# nrf7140_application register map
Vendor: Nordic Semiconductor; Series: nRF71; File version: 1
CPU: CM33 r0p4, little endian, MPU, FPU, 3 interrupt priority bits, 480 interrupts, 8 SAU regions
Registers are 32-bit, read-write, reset 0x0 unless marked. A register's access mark holds for its fields unless they carry their own. Offsets are from the block's base; [hi:lo] are bit positions; lines under a group give offsets from that group; {n}, {i} and the like mark numbered series; 'fields as' and 'values as' point back to an identical list.

## GLOBAL_GPU_NS — GPU
Base 0x49000000
0x100 EVENTS_CORE — Event indicating that interrupt triggered at GPU core
  [0] EVENTS_CORE
    0=NotGenerated (Event not generated); 1=Generated (Event generated)
0x104 EVENTS_SYSERROR — Event indicating
  [0] EVENTS_SYSERROR
    values as EVENTS_CORE.EVENTS_CORE
0x108 EVENTS_FREEZE — Freeze GPU
  [0] EVENTS_FREEZE
    values as EVENTS_CORE.EVENTS_CORE
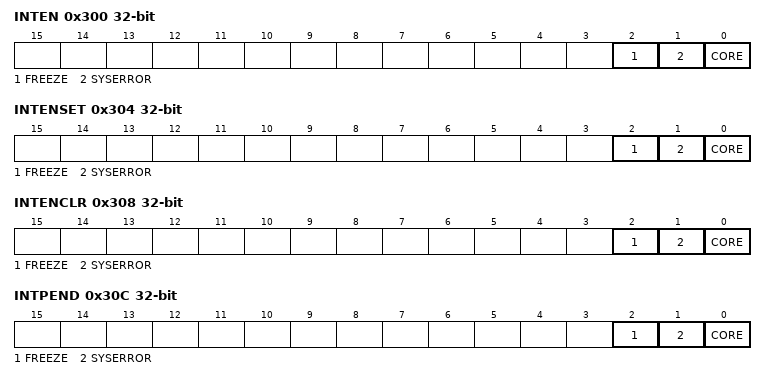
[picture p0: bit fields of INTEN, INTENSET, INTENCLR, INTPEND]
0x300 INTEN — Enable or disable interrupt
  [all] fields
    0=Disabled; 1=Enabled
  [2] FREEZE — Enable or disable interrupt for event FREEZE
  [1] SYSERROR — Enable or disable interrupt for event SYSERROR
  [0] CORE — Enable or disable interrupt for event CORE
0x304 INTENSET — Enable interrupt
  [all] fields
    on read: 0=Disabled (Read: Disabled); 1=Enabled (Read: Enabled) | on write: 1=Set (Enable)
  [2] FREEZE — Write '1' to enable interrupt for event FREEZE
  [1] SYSERROR — Write '1' to enable interrupt for event SYSERROR
  [0] CORE — Write '1' to enable interrupt for event CORE
0x308 INTENCLR — Disable interrupt
  [all] fields
    on read: 0=Disabled (Read: Disabled); 1=Enabled (Read: Enabled) | on write: 1=Clear (Disable)
  [2] FREEZE — Write '1' to disable interrupt for event FREEZE
  [1] SYSERROR — Write '1' to disable interrupt for event SYSERROR
  [0] CORE — Write '1' to disable interrupt for event CORE
0x30C INTPEND ro — Pending interrupts
  [all] fields
    on read: 0=NotPending (Read: Not pending); 1=Pending (Read: Pending)
  [2] FREEZE — Read pending status of interrupt for event FREEZE
  [1] SYSERROR — Read pending status of interrupt for event SYSERROR
  [0] CORE — Read pending status of interrupt for event CORE
0x500 ENABLE — Enable GPU.
  [0] EN — Enable
    0=Disabled (GPU disabled.); 1=Enabled (GPU enabled.)
0x504 FLAG — FLAG information for FREEZE assertion.
  [3:0] FLAG — Writing '1' sets the flag breakpoint, writing '0' resumes the breakpoint. Reading reads the value of the flag.
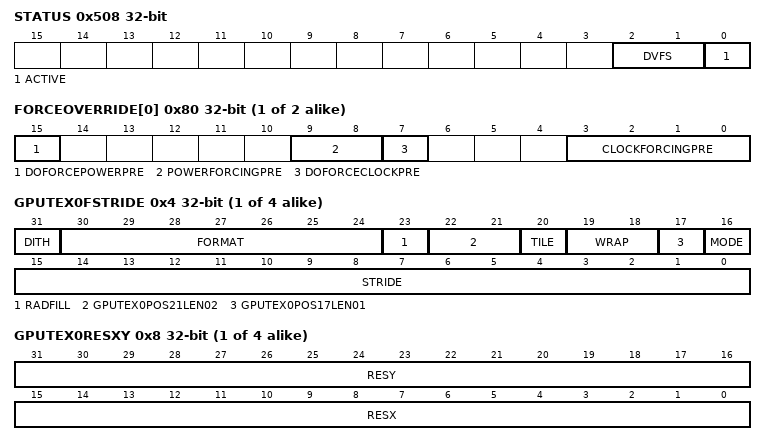
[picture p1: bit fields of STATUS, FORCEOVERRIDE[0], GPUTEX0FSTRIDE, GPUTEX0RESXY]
0x508 STATUS — GPU ACTIVE and DVFS status fields.
  [2:1] DVFS — Frequency reduction request for GPU core clock.
  [0] ACTIVE — GPU active indication
    1=BUSY (GPU is Busy); 0=IDLE (GPU is idle)
0xF00 PCGCSLAVE group — Unspecified
  {0x0+4j} PENALTY[{j}] (j=0..1) reset 0xFFFFFFFC — Description collection: Penalty level for power/clock pair n. When FULL_PCP_ZERO feature is not supported, PENALTY[0] address overlaps the PENALTY0 address and register description for PENALTY[0] is not valid.
    [1:0] PENALTY — Penalty level
  0x00 PENALTY0 (alternate view of PENALTY[*]) — Penalty level for power/clock pair 0. The register description is valid only when FULL_PCP_ZERO feature is not supported
    [1:0] PENALTY ro — Penalty level
  {0x80+4j} FORCEOVERRIDE[{j}] (j=0..1) — Description collection: Force override of power/clock pair n.
    [15] DOFORCEPOWERPRE, [9:8] POWERFORCINGPRE, [7] DOFORCECLOCKPRE, [3:0] CLOCKFORCINGPRE
0x1000 CORE group — Unspecified
  {0x0+0x10*j} GPUTEX{j}BASE (j=0..3) — Base address of drawing surface {j}.
    [31:0] BASE — Specifies the base address or drawing surface {j}.
  {0x4+0x10*j} GPUTEX{j}FSTRIDE (j=0..3) — Image {j} Mode and Stride
    [31] DITH — If set for destination texture, enables color dithering.
    [30:24] FORMAT — Specifies the image format
    [23] RADFILL — Radial fill enable
    [22:21] GPUTEX{j}POS21LEN02 wo
    [20] TILE — Enables the Tile Mode.
    [19:18] WRAP — Specifies the image wrapping mode (applicable only for Textures not for Framebuffer).
    [17] GPUTEX{j}POS17LEN01 wo
    [16] MODE — Specifies the image mode (applicable only for Textures not for Framebuffer)
    [15:0] STRIDE — Specifies the image stride distance in bytes from one scanline to another (signed)
  {0x8+0x10*j} GPUTEX{j}RESXY (j=0..3) — Image {j} Resolution
    [31:16] RESY — Specifies the size of resolution Y
    [15:0] RESX — Specifies the size of resolution X
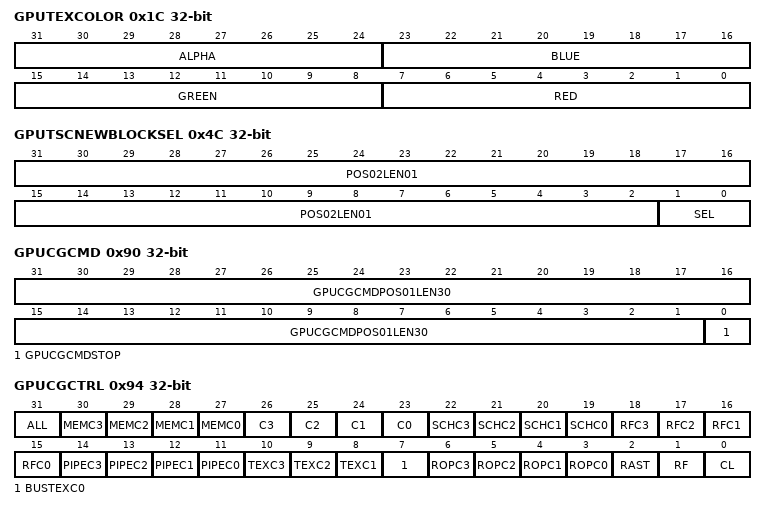
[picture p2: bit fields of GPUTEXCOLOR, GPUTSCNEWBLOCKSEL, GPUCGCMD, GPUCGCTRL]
  0x1C GPUTEXCOLOR — Texture Map's default color (for use with Luminance and Alpha-only color formats)
    [31:24] ALPHA — Specifies the Alpha (A) value
    [23:16] BLUE — Specifies the Blue (B) value
    [15:8] GREEN — Specifies the Green (G) value
    [7:0] RED — Specifies the Red (R) value
  0x48 GPUTSCNEWBLOCKTRIG — Trigger to reset TSc block.
    [31:0] POS00LEN32
  0x4C GPUTSCNEWBLOCKSEL — Select how TSc block will be reset.
    [31:2] POS02LEN01
    [1:0] SEL — 0: Reset TSc block when NEMA_DRAW_CMD_NOHOLD is written or tesselator starts new geometry or NEMA_TSC_NEW_BLOCK_TRIG is written.
  0x80 GPUBREAKPOINT — Debug feature. Specifies a Breakpoint on the Command List
    [31:0] GPUBREAKPOINT — Specifies the Breakpoint ID
  0x8C GPUBREAKPOINTMASK — Debug feature. Specifies a Breakpoint Mask.
    [31:0] MASK — Specifies the Breakpoint Mask
  0x90 GPUCGCMD — Enable Clock gating
    [31:1] GPUCGCMDPOS01LEN30 wo
    [0] GPUCGCMDSTOP wo — When set to 1, the clock stops
  0x94 GPUCGCTRL — Clock gating controller
    [31] ALL — Disable clock gating for all modules
    [30] MEMC3
    [29] MEMC2
    [28] MEMC1
    [27] MEMC0 — Disable clock gating for Core 0 Instruction Memory
    [26] C3
    [25] C2
    [24] C1
    [23] C0 — Disable clock gating for Core 0
    [22] SCHC3
    [21] SCHC2
    [20] SCHC1
    [19] SCHC0 — Disable clock gating for Core 0 Scheduler
    [18] RFC3
    [17] RFC2
    [16] RFC1
    [15] RFC0 — Disable clock gating for Core 0 Register File
    [14] PIPEC3
    [13] PIPEC2
    [12] PIPEC1
    [11] PIPEC0 — Disable clock gating for Core 0 Pipeline
    [10] TEXC3
    [9] TEXC2
    [8] TEXC1
    [7] BUSTEXC0 — Disable clock gating for the BusInterface (memory System) and Core 0 Texture Map
    [6] ROPC3
    [5] ROPC2
    [4] ROPC1
    [3] ROPC0 — Disable clock gating for the Render Output Unit of core 0
    [2] RAST — Disable clock gating for the NemaP Rasterizer
    [1] RF — Disable clock gating for the NemaP Configuration Register File
    [0] CL — Disable clock gating for the Command List Processor
  0x98 GPUDIRTYMIN reset 0xFFFFFFFF — Read the Dirty_Min value. Resets dirty region to resolution size on write function.
    [31:0] DIRTYMIN — Write any value to reset dirty region to resolution size
  0x9C GPUDIRTYMAX — Read the Dirty_Max value
    [31:0] DIRTYMAX ro — Read the Dirty_max value
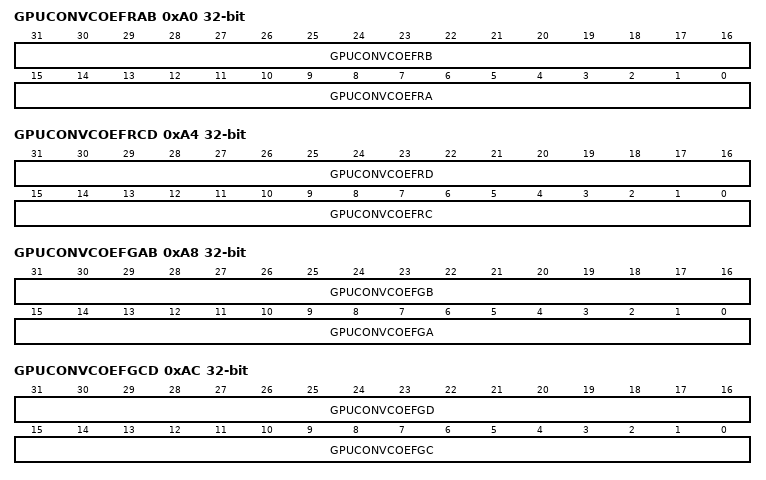
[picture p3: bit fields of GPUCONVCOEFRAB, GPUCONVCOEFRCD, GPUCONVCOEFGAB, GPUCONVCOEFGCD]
  0xA0 GPUCONVCOEFRAB — Specifies the YUV coefficients for Red color. Part one
    [31:16] GPUCONVCOEFRB — Specifies the YUV coefficients for Red color. Part B
    [15:0] GPUCONVCOEFRA — Specifies the YUV coefficients for Red color. Part A
  0xA4 GPUCONVCOEFRCD — Specifies the YUV coefficients for Red color. Part two
    [31:16] GPUCONVCOEFRD — Specifies the YUV coefficients for Red color. Part D
    [15:0] GPUCONVCOEFRC — Specifies the YUV coefficients for Red color. Part C
  0xA8 GPUCONVCOEFGAB — Specifies the YUV coefficients for Green color. Part one
    [31:16] GPUCONVCOEFGB — Specifies the YUV coefficients for Green color. Part B
    [15:0] GPUCONVCOEFGA — Specifies the YUV coefficients for Green color. Part A
  0xAC GPUCONVCOEFGCD — Specifies the YUV coefficients for Gren color. Part two
    [31:16] GPUCONVCOEFGD — Specifies the YUV coefficients for Green color. Part D
    [15:0] GPUCONVCOEFGC — Specifies the YUV coefficients for Green color. Part C
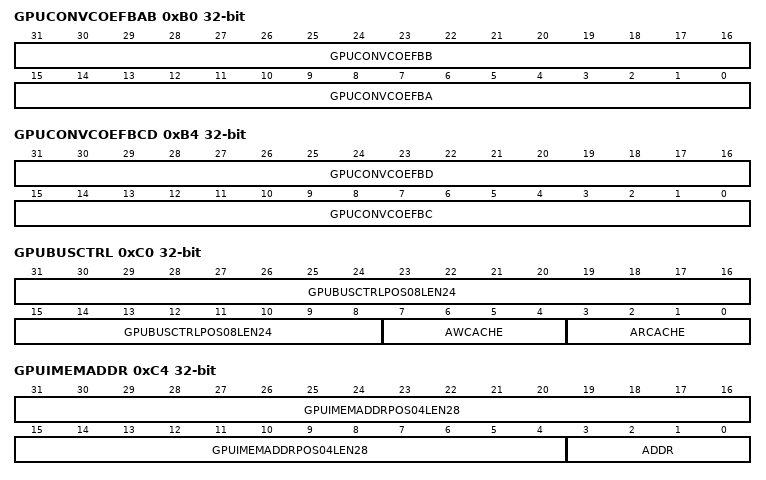
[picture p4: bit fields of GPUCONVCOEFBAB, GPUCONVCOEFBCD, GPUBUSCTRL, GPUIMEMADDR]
  0xB0 GPUCONVCOEFBAB — Specifies the YUV coefficients for Blue color. Part one
    [31:16] GPUCONVCOEFBB — Specifies the YUV coefficients for Blue color. Part B
    [15:0] GPUCONVCOEFBA — Specifies the YUV coefficients for Blue color. Part A
  0xB4 GPUCONVCOEFBCD — Specifies the YUV coefficients for Blue color. Part two
    [31:16] GPUCONVCOEFBD — Specifies the YUV coefficients for Blue color. Part D
    [15:0] GPUCONVCOEFBC — Specifies the YUV coefficients for Blue color. Part C
  0xB8 GPUCRCM0 — On read returns the CRC form Write Channel 0
    [31:0] GPUCRCM0 — NEMA_CRC_M0
  0xBC GPUCRCM1 — On read returns the CRC form Write Channel 1
    [31:0] GPUCRCM1 — NEMA_CRC_M1
  0xC0 GPUBUSCTRL — Indicates the value of the AWCACHE and the ARCACHE signals of the AXI Bus Interface.
    [31:8] GPUBUSCTRLPOS08LEN24
    [7:4] AWCACHE — Specifies the value of the output AWCACHE signal of the AXI Master Write Bus Interface
    [3:0] ARCACHE — Specifies the value of the output ARCACHE signal of the AXI Master Read Bus Interface
  0xC4 GPUIMEMADDR — Load shader instruction memory address. This register can be auto incremented. Its content
    [31:4] GPUIMEMADDRPOS04LEN28
    [3:0] ADDR — Specifies the load shader instruction memory address
  0xC8 GPUIMEMDATALOW — The lower bits (31-0) of the 64-bit load shader instruction memory data
    [31:0] IMEMDATALOW — Specifies the lower bits (31-0) of the load shader instruction memory data
  0xCC GPUIMEMDATAHIGH — The higher bits (63-32) of the 64-bit load shader instruction memory data
    [31:0] IMEMDATAHIGH — Specifies the higher bits (63-32) of the load shader instruction memory data
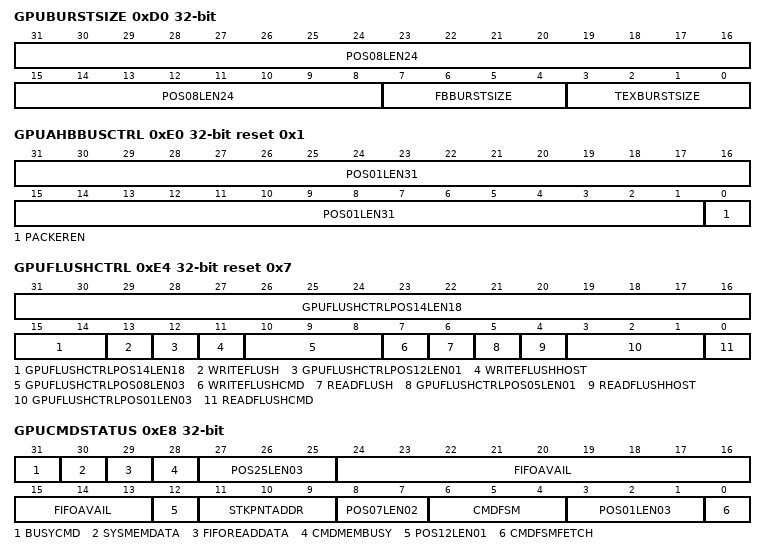
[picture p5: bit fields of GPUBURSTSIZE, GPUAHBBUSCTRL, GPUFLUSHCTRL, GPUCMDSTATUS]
  0xD0 GPUBURSTSIZE — Controls the size of the burst for the texture and framebuffer read.
    [31:8] POS08LEN24 ro
    [7:4] FBBURSTSIZE — Value of the framebuffer read burst size in log2(bytes).
    [3:0] TEXBURSTSIZE — Value of the texture read burst size in log2(bytes).
  0xE0 GPUAHBBUSCTRL reset 0x1 — Controls aspects of the AHB bus interface
    [31:1] POS01LEN31
    [0] PACKEREN — Enables or disables the packing of AHB transactions into 32-bit bursts when applicable
  0xE4 GPUFLUSHCTRL reset 0x7 — Controls the system flush
    [31:14] GPUFLUSHCTRLPOS14LEN18
    [13] WRITEFLUSH — When set to 1, flush write caches
    [12] GPUFLUSHCTRLPOS12LEN01
    [11] WRITEFLUSHHOST — If set to 1, the write caches are flushed when the Host triggers the Rasterizer (Register NEMA_DRAW_CMD_NOHOLD)
    [10:8] GPUFLUSHCTRLPOS08LEN03
    [7] WRITEFLUSHCMD — If set to 1, the write caches are flushed when the Command List Processor triggers the Rasterizer (Register NEMA_DRAW_CMD_NOHOLD)
    [6] READFLUSH — When set to 1, flush read caches
    [5] GPUFLUSHCTRLPOS05LEN01
    [4] READFLUSHHOST — If set to 1, the read caches are fluhsed when the Host triggers the Rasterizer (Register NEMA_DRAW_CMD_NOHOLD)
    [3:1] GPUFLUSHCTRLPOS01LEN03
    [0] READFLUSHCMD — If set to 1, the read caches are flushed when the Command List Processor triggers the Rasterizer (Register NEMA_DRAW_CMD_NOHOLD)
  0xE8 GPUCMDSTATUS — On read, returns internal CL processor status.
    [31] BUSYCMD — Indicates if the Command List Processor is busy
    [30] SYSMEMDATA — Indicates if there are data available in System Memory
    [29] FIFOREADDATA — Indicates if there are available data to read from FIFO
    [28] CMDMEMBUSY — Indicates if the Command List Processor System Memory is busy
    [27:25] POS25LEN03
    [24:13] FIFOAVAIL — Show how many cells are still available in FIFO
    [12] POS12LEN01
    [11:9] STKPNTADDR — Show the address of the stack pointer
    [8:7] POS07LEN02
    [6:4] CMDFSM — Indicates the state of CMDList internal FSM.
    [3:1] POS01LEN03
    [0] CMDFSMFETCH — Indicates the state of the FSM responsible for fetching
  0xEC GPUCMDRINGSTOP — Ring Buffer's pointer.
    [31:0] CMDRINGSTOP — Stores the Ring Buffer's last written address
  0xF0 GPUCMDADDR — Command list base address.
    [31:0] CMDADDR — Specifies the base address of every new command list ready to be executed
  0xF4 GPUCMDSIZE — Command list length in words(32-bits)
    [31:0] CMDSIZE — Specifies the length of the command list ready to be executed.
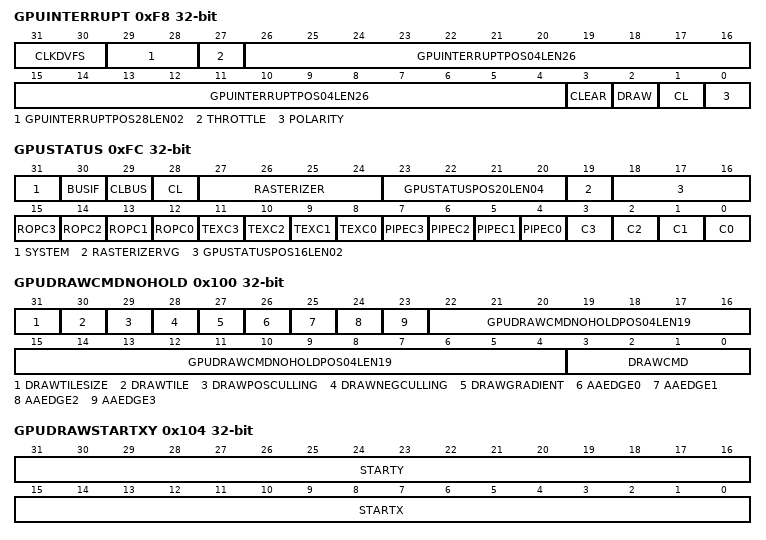
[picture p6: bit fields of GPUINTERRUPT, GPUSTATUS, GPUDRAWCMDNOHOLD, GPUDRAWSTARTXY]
  0xF8 GPUINTERRUPT — Interrupt control register
    [31:30] CLKDVFS — Specify the core_clk_dvfs output
    [29:28] GPUINTERRUPTPOS28LEN02
    [27] THROTTLE — When set to 1, the throttle signal will be ignored.
    [26:4] GPUINTERRUPTPOS04LEN26
    [3] CLEAR — When set to 1, the interrupt in the NEMA_IRQ_ID register is cleared
    [2] DRAW — When set to 1, signals an interrupt at the end of a drawing command
    [1] CL — When set to 1, signals an interrupt at the end of a command list
    [0] POLARITY — 1: IRQ signal is active low
  0xFC GPUSTATUS — On read, returns Nema's status.
    [31] SYSTEM — Indicates if the system is busy
    [30] BUSIF — Indicates if the Bus Interface Unit is busy
    [29] CLBUS — Indicates if the Command List bus is busy
    [28] CL — Indicates if the Command List Processor is busy
    [27:24] RASTERIZER — Indicate if the Rasterizer Unit is busy
    [23:20] GPUSTATUSPOS20LEN04
    [19] RASTERIZERVG — Indicates if the Rasterizer Vertex Matrix Multiplication Unit and Tesselation Unit are busy
    [18:16] GPUSTATUSPOS16LEN02
    [15] ROPC3
    [14] ROPC2
    [13] ROPC1
    [12] ROPC0 — Indicates if the Core 0 Render Output Unit is busy
    [11] TEXC3
    [10] TEXC2
    [9] TEXC1
    [8] TEXC0 — Indicates if the Core 0 Texture Map Unit is busy
    [7] PIPEC3
    [6] PIPEC2
    [5] PIPEC1
    [4] PIPEC0 — Indicates if the Core 0 graphics pipeline is busy
    [3] C3
    [2] C2
    [1] C1
    [0] C0 — Indicates if the Core 0 is busy
  0x100 GPUDRAWCMDNOHOLD — Rasterizer Command (e.g. draw triangle, rectangle etc)
    [31] DRAWTILESIZE — When set to 1, tile size is 2x2
    [30] DRAWTILE — When set to 1, tile mode is enabled
    [29] DRAWPOSCULLING — When set to 1, positive culling (counter-clockwise) is enabled
    [28] DRAWNEGCULLING — When set to 1, negative culling (clockwise) is enabled
    [27] DRAWGRADIENT — When set to 1, color gradient is enabled
    [26-n] AAEDGE{n} (n=0..3) — When set to 1, Antialiasing feature is enabled for edge {n}
    [22:4] GPUDRAWCMDNOHOLDPOS04LEN19
    [3:0] DRAWCMD — Draw Command
  0x104 GPUDRAWSTARTXY — Vertex 0 drawing primitive. This register is used only for integer values. For greater accuracy
    [31:16] STARTY — Specifies the Y coordinate (integer value) of vertex 0
    [15:0] STARTX — Specifies the X coordinate (integer value) of vertex 0
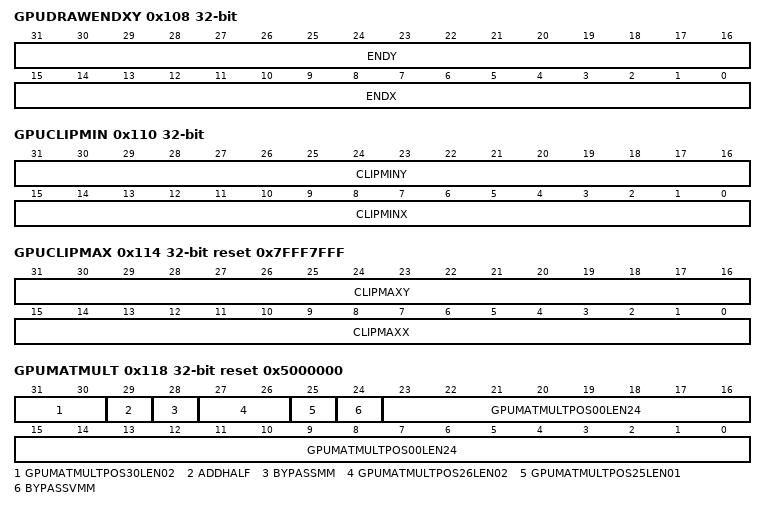
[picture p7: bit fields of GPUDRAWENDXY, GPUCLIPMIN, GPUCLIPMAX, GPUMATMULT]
  0x108 GPUDRAWENDXY — Vertex 1 drawing primitive. This register is used only for integer values. For greater accuracy
    [31:16] ENDY — Specifies the Y coordinate (integer value) of vertex 1
    [15:0] ENDX — Specifies the X coordinate (integer value) of vertex 1
  0x10C DRAWFANX — X coordinate of the Fan center point. Its content should be considered volatile.
    [31:0] X — Specifies the X coordinate of bezier vertex 4 drawing primitive (fixed point 16.16 format)
  0x110 GPUCLIPMIN — Clipping Rectangle upper left vertex
    [31:16] CLIPMINY — Define the upper left Y coordinate
    [15:0] CLIPMINX — Define the upper left X coordinate
  0x114 GPUCLIPMAX reset 0x7FFF7FFF — Clipping Rectangle bottom right vertex
    [31:16] CLIPMAXY — Define the bottom left Y coordinate
    [15:0] CLIPMAXX — Define the bottom left X coordinate
  0x118 GPUMATMULT reset 0x5000000 — Rasterizer matrix multiplication control. This register is partially updated
    [31:30] GPUMATMULTPOS30LEN02
    [29] ADDHALF — When set to 1, the 0.5 value is added to the X and Y coordinates
    [28] BYPASSMM — When set to 1, the matrix multiplications are bypassed
    [27:26] GPUMATMULTPOS26LEN02 ro
    [25] GPUMATMULTPOS25LEN01
    [24] BYPASSVMM — When set to 1, the vertex matrix multiplications are bypassed
    [23:0] GPUMATMULTPOS00LEN24
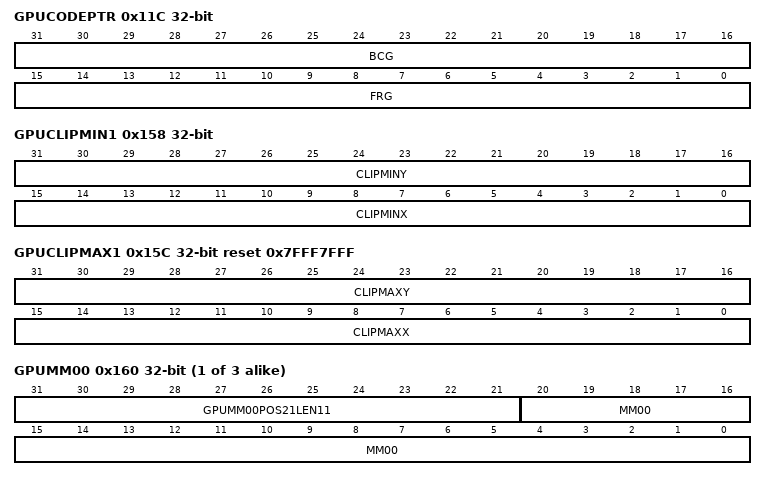
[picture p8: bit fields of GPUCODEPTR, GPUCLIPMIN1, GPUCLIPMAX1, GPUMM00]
  0x11C GPUCODEPTR — Shader code pointer
    [31:16] BCG — Specifies the pointer for the instruction that will be executed for the background pixels
    [15:0] FRG — Specifies the pointer for the instruction that will be executed for the foreground pixels
  0x120 GPUDRAWPT0X — X coordinate of vertex 0 drawing primitive. The value is 16.16 fixed point.
    [31:0] X — Specifies the X coordinate of vertex 0 drawing primitive (16.16 fixed point)
  0x124 GPUDRAWPT0Y — Y coordinate of vertex 0 drawing primitive. The value is 16.16 fixed point.
    [31:0] Y — Specifies the Y coordinate of vertex 0 drawing primitive (16.16 fixed point)
  0x128 DRAWFANY — Y coordinate of the Fan center point. Its content should be considered volatile.
    [31:0] Y — Specifies the X coordinate of bezier vertex 4 drawing primitive (fixed point 16.16 format)
  0x12C GPUDRAWCOLOR — Rasterizer drawing color for filling primitives
    [31:0] DRAWCOLOR — Specifies the drawing color for filling primitives
  0x130 GPUDRAWPT1X — X coordinate of vertex 1 drawing primitive. The value is 16.16 fixed point.
    [31:0] X — Specifies the X coordinate of vertex 1 drawing primitive (16.16 fixed point)
  0x134 GPUDRAWPT1Y — Y coordinate of vertex 1 drawing primitive. The value is 16.16 fixed point.
    [31:0] Y — Specifies the Y coordinate of vertex 1 drawing primitive (16.16 fixed point)
  0x138 GPUBYPASSADDR — Address of bypass mode of rasterizer setup access
  0x13C BYPASSDATA — Data and enable of bypass mode of rasterizer
    [31:0] GPUBYPASSDATA
  0x140 GPUDRAWPT2X — X coordinate of vertex 2 drawing primitive. The value is 16.16 fixed point
    [31:0] X — Specifies the X coordinate of vertex 2 drawing primitive (16.16 fixed point)
  0x144 GPUDRAWPT2Y — Y coordinate of vertex 2 drawing primitive. The value is 16.16 fixed point
    [31:0] Y — Specifies the Y coordinate of vertex 2 drawing primitive (16.16 fixed point)
  0x148 GPUCLID — Command List ID Key
    [31:0] CLID — Specifies the last executed command list
  0x150 GPUDRAWPT3X — X coordinate of vertex 3 drawing primitive. The value is 16.16 fixed point
    [31:0] X — Specifies the X coordinate of vertex 3 drawing primitive (16.16 fixed point)
  0x154 GPUDRAWPT3Y — Y coordinate of vertex 3 drawing primitive. The value is 16.16 fixed point
    [31:0] Y — Specifies the Y coordinate of vertex 3 drawing primitive (16.16 fixed point)
  0x158 GPUCLIPMIN1 — Second Clipping Rectangle upper left vertex
    fields as CORE.GPUCLIPMIN
  0x15C GPUCLIPMAX1 reset 0x7FFF7FFF — Second Clipping Rectangle bottom right vertex
    fields as CORE.GPUCLIPMAX
  {0x160+4j} GPUMM{j:02} (j=0..2) — (0,{j}) matrix floating point element. On read return the floating point value with the selected characteristics
    [31:21] GPUMM{j:02}POS21LEN11
    [20:0] MM{j:02} — Specifies the (0,{j}) element
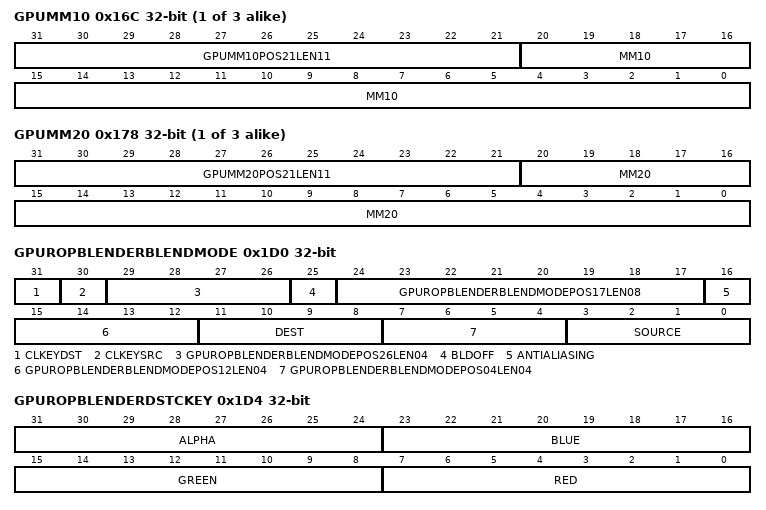
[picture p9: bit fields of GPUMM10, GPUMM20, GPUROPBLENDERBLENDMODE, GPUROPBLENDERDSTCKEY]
  {0x144+4j} GPUMM{j} (j=10..12) — (1,{j-10}) matrix floating point element. On read return the floating point value with the selected characteristics
    [31:21] GPUMM{j}POS21LEN11
    [20:0] MM{j} — Specifies the (1,{j-10}) element
  {0x128+4j} GPUMM{j} (j=20..22) — (2,{j-20}) matrix floating point element. On read return the floating point value with the selected characteristics
    [31:21] GPUMM{j}POS21LEN11
    [20:0] MM{j} — Specifies the (2,{j-20}) element
  0x184 GPUDEPTHSTARTL — Depth value of the STARTXY pixel. This register defines the
    [31:0] STARTL — Specifies the fractional part of the depth value of the STARTXY pixel
  0x188 GPUDEPTHSTARTH — Depth value of the STARTXY pixel. This register defines the
    [31:0] STARTH — Specifies the integral value of the depth value of the STARTXY pixel
  0x18C GPUDEPTHDXL — For each step at x-axis, depth value is added.
    [31:0] DXL — Specifies the fractional part of the added depth value for each step at x-axis
  0x190 GPUDEPTHDXH — For each step at x-axis, depth value is added.
    [31:0] DXH — Specifies the integral part of the added depth value for each step at x-axis
  0x194 GPUDEPTHDYL — For each step at y-axis, depth value is added.
    [31:0] DYL — Specifies the fractional part of the added depth value for each step at y-axis
  0x198 GPUDEPTHDYH — For each step at y-axis, depth value is added.
    [31:0] DYH — Specifies the integral part of the added depth value for each step at y-axis
  0x1A0 GPUREDDX — For each step at x-axis, Red (R) value is added.
    [31:0] DX — Specifies the added Red (R) value for each step at x-axis
  0x1A4 GPUREDDY — For each step at y-axis, Red (R) value is added.
    [31:0] DY — Specifies the added Red (R) value for each step at y-axis
  0x1A8 GPUGREDX — For each step at x-axis, Green (G) value is added.
    [31:0] DX — Specifies the added Green (G) value for each step at x-axis
  0x1AC GPUGREDY — For each step at y-axis, Green (G) value is added.
    [31:0] DY — Specifies the added Green (G) value for each step at y-axis
  0x1B0 GPUBLUDX — For each step at x-axis, Blue (B) value is added.
    [31:0] DX — Specifies the added Blue (B) value for each step at x-axis
  0x1B4 GPUBLUDY — For each step at y-axis, Blue (B) value is added.
    [31:0] DY — Specifies the added Blue (B) value for each step at y-axis
  0x1B8 GPUALFDX — For each step at x-axis, Alpha (A) value is added.
    [31:0] DX — Specifies the added Alpha (A) value for each step at x-axis
  0x1BC GPUALFDY — For each step at y-axis, Alpha (A) value is added.
    [31:0] DY — Specifies the added Alpha (A) value for each step at y-axis
  0x1C0 GPUREDINIT — Red (R) value of the STARTXY pixel. The value is 16,16 fixed point
    [31:0] INIT — Specifies the Red (R) value of the STARTXY pixel
  0x1C4 GPUGREINIT — Green (G) value of the STARTXY pixel. The value is 16,16 fixed point
    [31:0] INIT — Specifies the Green (G) value of the STARTXY pixel
  0x1C8 GPUBLUINIT — Blue (B) value of the STARTXY pixel. The value is 16,16 fixed point
    [31:0] INIT — Specifies the Blue (B) value of the STARTXY pixel
  0x1CC GPUALFINIT — Alpha (A) value of the STARTXY pixel. The value is 16,16 fixed point
    [31:0] INIT — Specifies the Alpha (A) value of the STARTXY pixel
  0x1D0 GPUROPBLENDERBLENDMODE — Blending Modes for different calculations between the source
    [31] CLKEYDST — If set, enables Destination Color Keying
    [30] CLKEYSRC — If set, enables Source Color Keying
    [29:26] GPUROPBLENDERBLENDMODEPOS26LEN04
    [25] BLDOFF — If set, enables Negative Destination Color Keying.
    [24:17] GPUROPBLENDERBLENDMODEPOS17LEN08
    [16] ANTIALIASING — If set, disables Antialiasing
    [15:12] GPUROPBLENDERBLENDMODEPOS12LEN04
    [11:8] DEST — Blending mode of the stored pixel in the FrameBuffer (destination pixel)
    [7:4] GPUROPBLENDERBLENDMODEPOS04LEN04
    [3:0] SOURCE — Blending mode of the current pixel (source pixel)
  0x1D4 GPUROPBLENDERDSTCKEY — When Color Keying is enabled. The new pixel is written in the Frame Buffer,
    fields as CORE.GPUTEXCOLOR
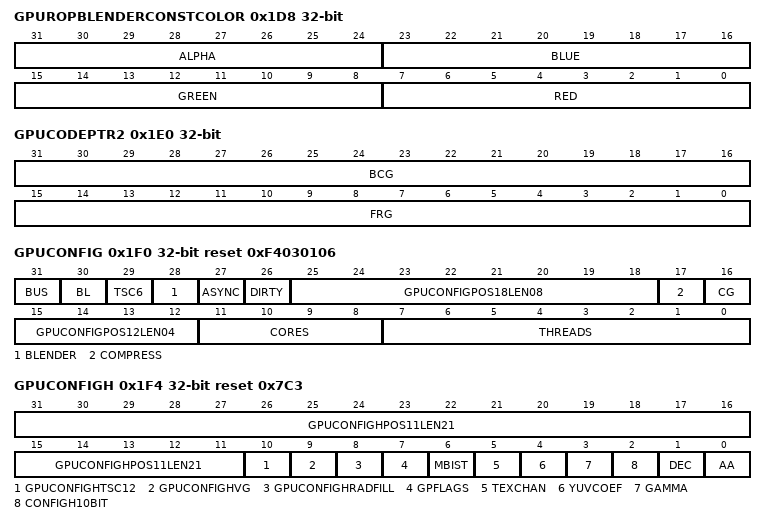
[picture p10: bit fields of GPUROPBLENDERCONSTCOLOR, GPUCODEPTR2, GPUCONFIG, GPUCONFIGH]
  0x1D8 GPUROPBLENDERCONSTCOLOR — Constant Color value which is used for blending when the blending modes.
    fields as CORE.GPUTEXCOLOR
  0x1DC GPUIPVERSION reset 0x230600 — Returns the current GPU IP version
    [31:0] UNEMAVERSION ro — The current version of the GPU IP
  0x1E0 GPUCODEPTR2 — Shader code pointer
    [31:16] BCG — Specifies the pointer for the instruction that will be executed for the background pixels if we are working on neg_area geometries (rasterizer)
    [15:0] FRG — Specifies the pointer for the instruction that will be executed for the foreground pixels if we are working on neg_area geometries (rasterizer)
  0x1EC GPUIDREG reset 0x86362000 — GPU ID Register (fixed value)
    [31:0] IDREG ro — The fixed value is 0x86362000
  0x1F0 GPUCONFIG reset 0xF4030106 — GPU configuration status
    [31] BUS ro — When set to 1, indicates that the master bus is AXI
    [30] BL ro — When set to 1, indicates that Bilinear filtering is enabled
    [29] TSC6 ro — When set to 1, indicates that TSC6 compression mode is enabled.
    [28] BLENDER ro — When set to 1, indicates that H/W Blender is enabled
    [27] ASYNC ro — When set to 1, Bus to Memory is Asynchronous to core clock
    [26] DIRTY ro — When set to 1, indicates that Dirty Region is enabled
    [25:18] GPUCONFIGPOS18LEN08 ro
    [17] COMPRESS ro — When set to 1, indicates that TSC compression mode is enabled
    [16] CG ro — When set to 1, indicates that clock gating is enabled
    [15:12] GPUCONFIGPOS12LEN04 ro
    [11:8] CORES ro — Indicates the number of cores
    [7:0] THREADS ro — Indicates the log2 number of threads
  0x1F4 GPUCONFIGH reset 0x7C3 — GPU configuration status (high bits)
    [31:11] GPUCONFIGHPOS11LEN21 ro
    [10] GPUCONFIGHTSC12 ro — When set to 1, indicates that TSC12 compression mode is enabled
    [9] GPUCONFIGHVG ro — Indicates that NemaVG is enabled
    [8] GPUCONFIGHRADFILL ro — Indicates that Radial Fill is enabled
    [7] GPFLAGS ro — Indicates that external debug interface (GP_FLAG, SYSERROR_IRQ, FREEZE) is enabled
    [6] MBIST ro — Indicates that separate logic/mem Clock Gating is enabled
    [5] TEXCHAN ro — Indicates that Texture map unit has two channels
    [4] YUVCOEF ro — Indicates that YUV coefficients are present
    [3] GAMMA ro — Indicates that Gamma Correction is enabled
    [2] CONFIGH10BIT ro — Indicates that 10-bit precision is selected
    [1] DEC ro — Indicates that the TSc Framebuffer/Texture Decompression is enabled
    [0] AA ro — Indicates that the Antialiasing feature is enabled
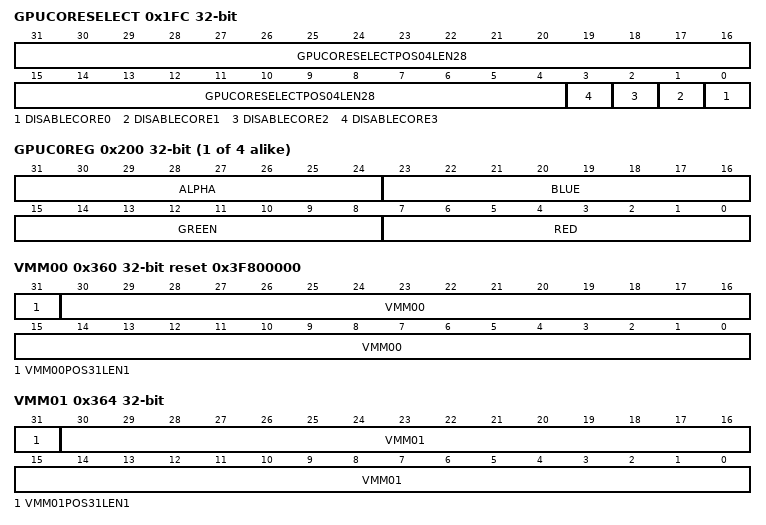
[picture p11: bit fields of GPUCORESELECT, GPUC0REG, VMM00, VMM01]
  0x1FC GPUCORESELECT — Select which of the available cores will be active
    [31:4] GPUCORESELECTPOS04LEN28
    [n] DISABLECORE{n} (n=0..3) — set to deactivate core {n}
  {0x200+4j} GPUC{j}REG (j=0..3) — A 32-bit integer RGBA value is stored in constant register {j} for fragment calculations.
    [31:24] ALPHA wo — Specifies the Alpha (A) value
    [23:16] BLUE wo — Specifies the Blue (B) value
    [15:8] GREEN wo — Specifies the Green (G) value
    [7:0] RED wo — Specifies the Red (R) value
  {0x320+0x10*j} DRAWPT{j}X (j=0..3) — X coordinate of bezier vertex {j} drawing primitive.
    [31:0] X wo — Specifies the X coordinate of bezier vertex {j} drawing primitive (fp32 format)
  {0x324+0x10*j} DRAWPT{j}Y (j=0..3) — Y coordinate of bezier vertex {j} drawing primitive.
    [31:0] Y wo — Specifies the Y coordinate of bezier vertex {j} drawing primitive (fp32 format)
  0x328 DRAWFPFANX — X coordinate of the Fan center point. Its content should be considered volatile.
    [31:0] X wo — Specifies the X coordinate of bezier vertex 4 drawing primitive (fp32 format)
  0x32C DRAWFPFANY — Y coordinate of the Fan center point. Its content should be considered volatile.
    [31:0] Y wo — Specifies the X coordinate of bezier vertex 4 drawing primitive (fp32 format)
  0x360 VMM00 reset 0x3F800000 — (0,0) Bezier Vertex Transformation matrix floating point element. On read return the floating point value with the selected characteristics
    [31] VMM00POS31LEN1
    [30:0] VMM00 — Specifies the (0,0) element
  0x364 VMM01 — (0,1) Bezier Vertex Transformation matrix floating point element. On read return the floating point value with the selected characteristics
    [31] VMM01POS31LEN1
    [30:0] VMM01 — Specifies the (0,1) element
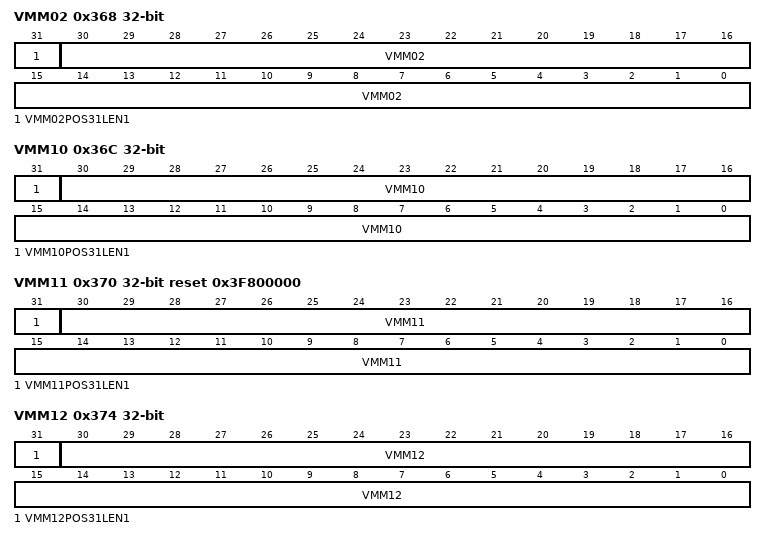
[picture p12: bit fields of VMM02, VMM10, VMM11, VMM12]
  0x368 VMM02 — (0,2) Bezier Vertex Transformation matrix floating point element. On read return the floating point value with the selected characteristics
    [31] VMM02POS31LEN1
    [30:0] VMM02 — Specifies the (0,2) element
  0x36C VMM10 — (1,0) Bezier Vertex Transformation matrix floating point element. On read return the floating point value with the selected characteristics
    [31] VMM10POS31LEN1
    [30:0] VMM10 — Specifies the (1,0) element
  0x370 VMM11 reset 0x3F800000 — (1,1) Bezier Vertex Transformation matrix floating point element. On read return the floating point value with the selected characteristics
    [31] VMM11POS31LEN1
    [30:0] VMM11 — Specifies the (1,1) element
  0x374 VMM12 — (1,2) Bezier Vertex Transformation matrix floating point element. On read return the floating point value with the selected characteristics
    [31] VMM12POS31LEN1
    [30:0] VMM12 — Specifies the (1,2) element
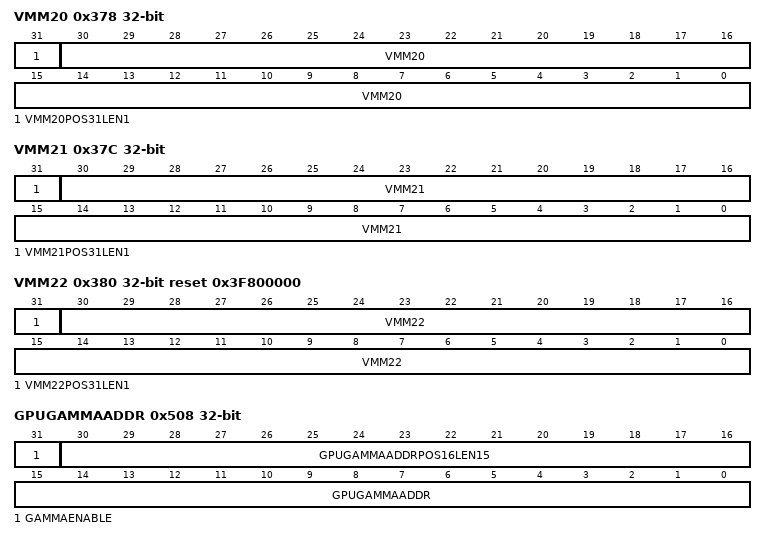
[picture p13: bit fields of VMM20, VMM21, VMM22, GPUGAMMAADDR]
  0x378 VMM20 — (2,0) Bezier Vertex Transformation matrix floating point element. On read return the floating point value with the selected characteristics
    [31] VMM20POS31LEN1
    [30:0] VMM20 — Specifies the (2,0) element
  0x37C VMM21 — (2,1) Bezier Vertex Transformation matrix floating point element. On read return the floating point value with the selected characteristics
    [31] VMM21POS31LEN1
    [30:0] VMM21 — Specifies the (2,1) element
  0x380 VMM22 reset 0x3F800000 — (2,2) Bezier Vertex Transformation matrix floating point element. On read return the floating point value with the selected characteristics
    [31] VMM22POS31LEN1
    [30:0] VMM22 — Specifies the (2,2) element
  0x4D0 GPUCOORDMASK reset 0xFFF — Inverted mask for rasterizer coordinates
  0x4D4 DRAWFLATNESS reset 0x8000 — Width in pixels of Bezier Curve flatness. (Lower values improve accuracy)
    [31:0] FLATNESS — Specifies the convergence point of de Casteljau's Algorithm for drawing Bezier Curves (fixed point 16.16 format)
  0x508 GPUGAMMAADDR — Enables Gamma LUTs and Set the internal address
    [31] GAMMAENABLE — Enables the Gamma Luts
    [30:16] GPUGAMMAADDRPOS16LEN15
    [15:0] GPUGAMMAADDR — Specifies the internal address of LUTs
  0x510 GPUGAMMADATA — Specify the Gamma LUT data
    [31:0] GPUGAMMADATA — Specify the Gamma LUT data for the specified address
  {0x800+0x10*j} GPUTEX{j}BASEL (j=0..3) — Texture mapping registers of drawing surface {j}.(low bits)
    [31:0] BASEL — Image {j} Base Address low bits
  {0x804+0x10*j} GPUTEX{j}BASEH (j=0..3) — Texture mapping registers of drawing surface {j}.(high bits)
    [31:0] BASEH — Image {j} Base Address high bits
  0x840 GPUCMDRINGSTOPL — Ring Buffer's pointer Low bits.
    [31:0] CMDRINGSTOPL — Updates Ring Buffer's last written address Low bits.
  0x844 GPUCMDRINGSTOPH — Ring Buffer's pointer High bits.
    [31:0] CMDRINGSTOPH — Updates Ring Buffer's last written address High bits.
  0x848 GPUCMDADDRL — Command List base address Low bits
    [31:0] CMDADDRL — Command List address Low bits
  0x84C GPUCMDADDRH — Command List base address High bits
    [31:0] CMDADDRH — Command List address High bits
  0xFF0 GPUIRQID — Signals an interrupt when written
    [31:0] IRQID — Write any value to signal an interrupt
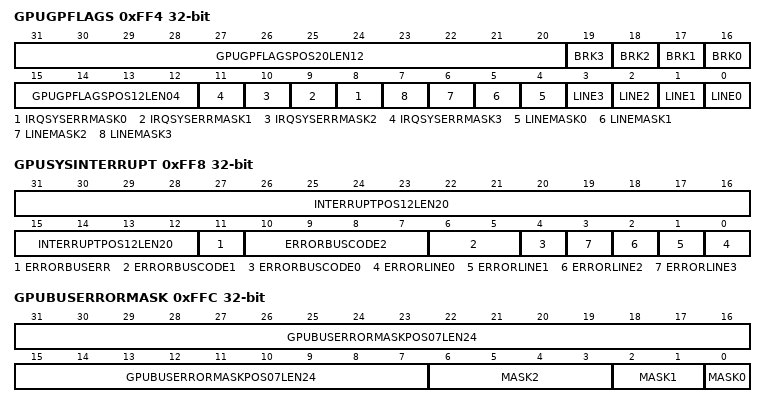
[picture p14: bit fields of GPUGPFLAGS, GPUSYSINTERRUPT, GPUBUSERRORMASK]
  0xFF4 GPUGPFLAGS — Stop/Break the command list when debugging
    [31:20] GPUGPFLAGSPOS20LEN12
    [n+16] BRK{n} (n=0..3) — When set to 1, set breakpoint for GP_FLAG line 0 if NEMA_GP_FLAGS[{n}] bit value is high.
    [15:12] GPUGPFLAGSPOS12LEN04
    [n+8] IRQSYSERRMASK{n} (n=0..3) — GP_FLAG_irqmask when set to 1 masks/enables the generation of the IRQ_SYSERROR from line {n}
    [n+4] LINEMASK{n} (n=0..3) — GP_FLAG_mask when set to 1 masks/enables the generation of the output FREEZE signal from line {n}
    [n] LINE{n} (n=0..3) — GP_FLAG line {n}.
  0xFF8 GPUSYSINTERRUPT — On Read: Returns the SYSERROR_IRQ ID. On write: Clears the SYSERROR_IRQ.
    [31:12] INTERRUPTPOS12LEN20
    [11] ERRORBUSERR — Indicates that a bus error has occurred.
    [10:7] ERRORBUSCODE2 — Indicates the Bus Error Code Interface.
    [6:5] ERRORBUSCODE1 — Indicates the Bus Error Code occurence direction (AXI only).
    [4] ERRORBUSCODE0 — Indicates the Interface Error Code(AXI only).
    [n] ERRORLINE{n} (n=0..3) — Indicates that IRQ_SYSERROR due to GP_FLAG line {n}.
  0xFFC GPUBUSERRORMASK — Sets the mask for the Buserror Interrupt.
    [31:7] GPUBUSERRORMASKPOS07LEN24
    [6:3] MASK2 — Sets the mask for the Bus Error Code Interface.
    [2:1] MASK1 — Sets the mask for the Bus Error Code occurence direction (AXI only).
    [0] MASK0
